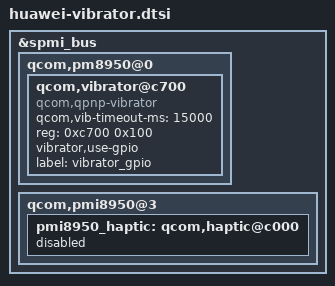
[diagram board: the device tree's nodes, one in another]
/* Copyright (c) 2015, The Linux Foundation. All rights reserved.
 *
 * This program is free software; you can redistribute it and/or modify
 * it under the terms of the GNU General Public License version 2 and
 * only version 2 as published by the Free Software Foundation.
 *
 * This program is distributed in the hope that it will be useful,
 * but WITHOUT ANY WARRANTY; without even the implied warranty of
 * MERCHANTABILITY or FITNESS FOR A PARTICULAR PURPOSE.  See the
 * GNU General Public License for more details.
 */

/* pmu vibrator */
&spmi_bus {
	qcom,pm8950@0 {
		qcom,vibrator@c700 {
			compatible = "qcom,qpnp-vibrator";
			qcom,vib-timeout-ms = <15000>;
			reg = <0xc700 0x100>;
			vibrator,use-gpio;
			label = "vibrator_gpio";
		};
	};

	qcom,pmi8950@3 {
		pmi8950_haptic: qcom,haptic@c000 {
			status = "disabled";
		};
	};
};
